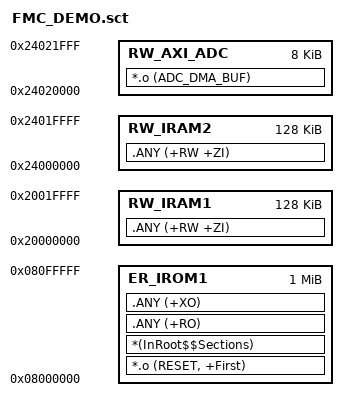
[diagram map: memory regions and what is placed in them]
; *************************************************************
; *** Scatter-Loading Description File generated by uVision ***
; *************************************************************

LR_IROM1 0x08000000 0x00100000  {    ; load region size_region
  ER_IROM1 0x08000000 0x00100000  {  ; load address = execution address
   *.o (RESET, +First)
   *(InRoot$$Sections)
   .ANY (+RO)
   .ANY (+XO)
  }
  RW_IRAM1 0x20000000 0x00020000  {  ; RW data
   .ANY (+RW +ZI)
  }
  RW_IRAM2 0x24000000 0x00020000  {
   .ANY (+RW +ZI)
  }
  ; ADC DMA 缓冲区：必须位于 AXI SRAM（DTCM 对 DMA2 不可达），32 字节对齐
  RW_AXI_ADC 0x24020000 0x00002000  {
   *.o (ADC_DMA_BUF)
  }
}

